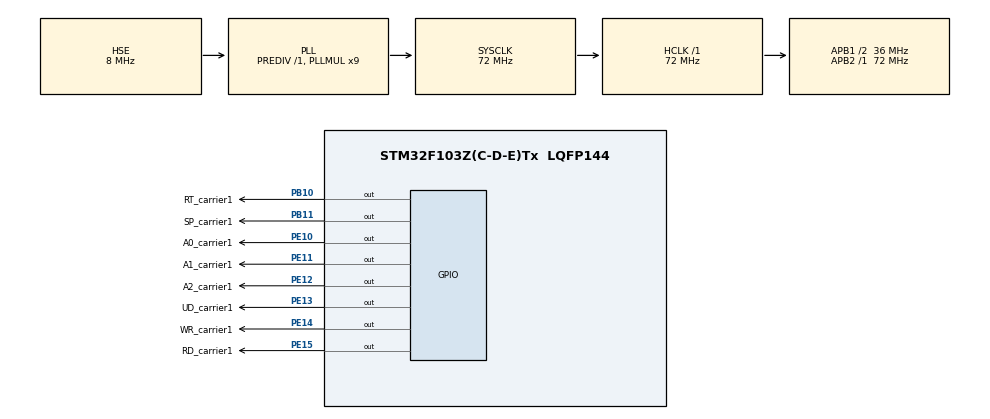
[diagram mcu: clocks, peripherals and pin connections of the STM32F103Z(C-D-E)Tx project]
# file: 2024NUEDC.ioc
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Mcu.Family=STM32F1
Mcu.Name=STM32F103Z(C-D-E)Tx
Mcu.Package=LQFP144
NVIC.PriorityGroup=NVIC_PRIORITYGROUP_4
OSC_IN.Mode=HSE-External-Oscillator
OSC_IN.Signal=RCC_OSC_IN
OSC_OUT.Mode=HSE-External-Oscillator
OSC_OUT.Signal=RCC_OSC_OUT
PA13.Mode=Serial_Wire
PA13.Signal=SYS_JTMS-SWDIO
PA14.Mode=Serial_Wire
PA14.Signal=SYS_JTCK-SWCLK
PB10.GPIO_Label=RT_carrier1
PB10.GPIO_ModeDefaultOutputPP=GPIO_MODE_OUTPUT_PP
PB10.GPIO_PuPd=GPIO_NOPULL
PB10.GPIO_Speed=GPIO_SPEED_FREQ_HIGH
PB10.PinState=GPIO_PIN_RESET
PB10.Signal=GPIO_Output
PB11.GPIO_Label=SP_carrier1
PB11.GPIO_ModeDefaultOutputPP=GPIO_MODE_OUTPUT_PP
PB11.GPIO_PuPd=GPIO_NOPULL
PB11.GPIO_Speed=GPIO_SPEED_FREQ_HIGH
PB11.PinState=GPIO_PIN_RESET
PB11.Signal=GPIO_Output
PE10.GPIO_Label=A0_carrier1
PE10.GPIO_ModeDefaultOutputPP=GPIO_MODE_OUTPUT_PP
PE10.GPIO_PuPd=GPIO_NOPULL
PE10.GPIO_Speed=GPIO_SPEED_FREQ_HIGH
PE10.PinState=GPIO_PIN_RESET
PE10.Signal=GPIO_Output
PE11.GPIO_Label=A1_carrier1
PE11.GPIO_ModeDefaultOutputPP=GPIO_MODE_OUTPUT_PP
PE11.GPIO_PuPd=GPIO_NOPULL
PE11.GPIO_Speed=GPIO_SPEED_FREQ_HIGH
PE11.PinState=GPIO_PIN_RESET
PE11.Signal=GPIO_Output
PE12.GPIO_Label=A2_carrier1
PE12.GPIO_ModeDefaultOutputPP=GPIO_MODE_OUTPUT_PP
PE12.GPIO_PuPd=GPIO_NOPULL
PE12.GPIO_Speed=GPIO_SPEED_FREQ_HIGH
PE12.PinState=GPIO_PIN_RESET
PE12.Signal=GPIO_Output
PE13.GPIO_Label=UD_carrier1
PE13.GPIO_ModeDefaultOutputPP=GPIO_MODE_OUTPUT_PP
PE13.GPIO_PuPd=GPIO_NOPULL
PE13.GPIO_Speed=GPIO_SPEED_FREQ_HIGH
PE13.PinState=GPIO_PIN_RESET
PE13.Signal=GPIO_Output
PE14.GPIO_Label=WR_carrier1
PE14.GPIO_Speed=GPIO_SPEED_FREQ_HIGH
PE14.Signal=GPIO_Output
PE15.GPIO_Label=RD_carrier1
PE15.GPIO_Speed=GPIO_SPEED_FREQ_HIGH
PE15.Signal=GPIO_Output
ProjectManager.HeapSize=0x200
ProjectManager.StackSize=0x400
ProjectManager.TargetToolchain=MDK-ARM V5.32
RCC.AHBFreq_Value=72000000
RCC.APB1CLKDivider=RCC_HCLK_DIV2
RCC.APB1Freq_Value=36000000
RCC.APB1TimFreq_Value=72000000
RCC.APB2Freq_Value=72000000
RCC.APB2TimFreq_Value=72000000
RCC.HCLKFreq_Value=72000000
RCC.PLLMUL=RCC_PLL_MUL9
RCC.PLLSourceVirtual=RCC_PLLSOURCE_HSE
RCC.SYSCLKFreq_VALUE=72000000
RCC.SYSCLKSource=RCC_SYSCLKSOURCE_PLLCLK
RCC.USBFreq_Value=72000000
VP_TIM1_VS_ClockSourceITR.Mode=TriggerSource_ITR0
board=custom

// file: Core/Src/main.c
/* USER CODE BEGIN Header */
/**
  ******************************************************************************
  * @file           : main.c
  * @brief          : Main program body
  ******************************************************************************
  * @attention
  *
  * Copyright (c) 2024 STMicroelectronics.
  * All rights reserved.
  *
  * This software is licensed under terms that can be found in the LICENSE file
  * in the root directory of this software component.
  * If no LICENSE file comes with this software, it is provided AS-IS.
  *
  ******************************************************************************
  */
/* USER CODE END Header */
#include "main.h"
#include "tim.h"
#include "gpio.h"

/* USER CODE BEGIN Includes */
#include "my_main.h"
#include "string.h"
/* USER CODE END Includes */

void SystemClock_Config(void);

int main(void)
{
  /* USER CODE BEGIN 1 */
    setup();
  /* USER CODE END 1 */

  /* MCU Configuration--------------------------------------------------------*/

  /* Reset of all peripherals, Initializes the Flash interface and the Systick. */
  HAL_Init();

  /* Configure the system clock */
  SystemClock_Config();

  /* Initialize all configured peripherals */
  MX_GPIO_Init();
  MX_TIM1_Init();

  /* Infinite loop */
  /* USER CODE BEGIN WHILE */
  while (1)
  {
      loop();
    /* USER CODE END WHILE */

  }
}

void SystemClock_Config(void)
{
  RCC_OscInitTypeDef RCC_OscInitStruct = {0};
  RCC_ClkInitTypeDef RCC_ClkInitStruct = {0};

  /** Initializes the RCC Oscillators according to the specified parameters
  * in the RCC_OscInitTypeDef structure.
  */
  RCC_OscInitStruct.OscillatorType = RCC_OSCILLATORTYPE_HSE;
  RCC_OscInitStruct.HSEState = RCC_HSE_ON;
  RCC_OscInitStruct.HSEPredivValue = RCC_HSE_PREDIV_DIV1;
  RCC_OscInitStruct.HSIState = RCC_HSI_ON;
  RCC_OscInitStruct.PLL.PLLState = RCC_PLL_ON;
  RCC_OscInitStruct.PLL.PLLSource = RCC_PLLSOURCE_HSE;
  RCC_OscInitStruct.PLL.PLLMUL = RCC_PLL_MUL9;
  if (HAL_RCC_OscConfig(&RCC_OscInitStruct) != HAL_OK)
  {
    Error_Handler();
  }

  /** Initializes the CPU, AHB and APB buses clocks
  */
  RCC_ClkInitStruct.ClockType = RCC_CLOCKTYPE_HCLK|RCC_CLOCKTYPE_SYSCLK
                              |RCC_CLOCKTYPE_PCLK1|RCC_CLOCKTYPE_PCLK2;
  RCC_ClkInitStruct.SYSCLKSource = RCC_SYSCLKSOURCE_PLLCLK;
  RCC_ClkInitStruct.AHBCLKDivider = RCC_SYSCLK_DIV1;
  RCC_ClkInitStruct.APB1CLKDivider = RCC_HCLK_DIV2;
  RCC_ClkInitStruct.APB2CLKDivider = RCC_HCLK_DIV1;

  if (HAL_RCC_ClockConfig(&RCC_ClkInitStruct, FLASH_LATENCY_2) != HAL_OK)
  {
    Error_Handler();
  }
}

void Error_Handler(void)
{
  __disable_irq();
  while (1)
  {
  }
}
